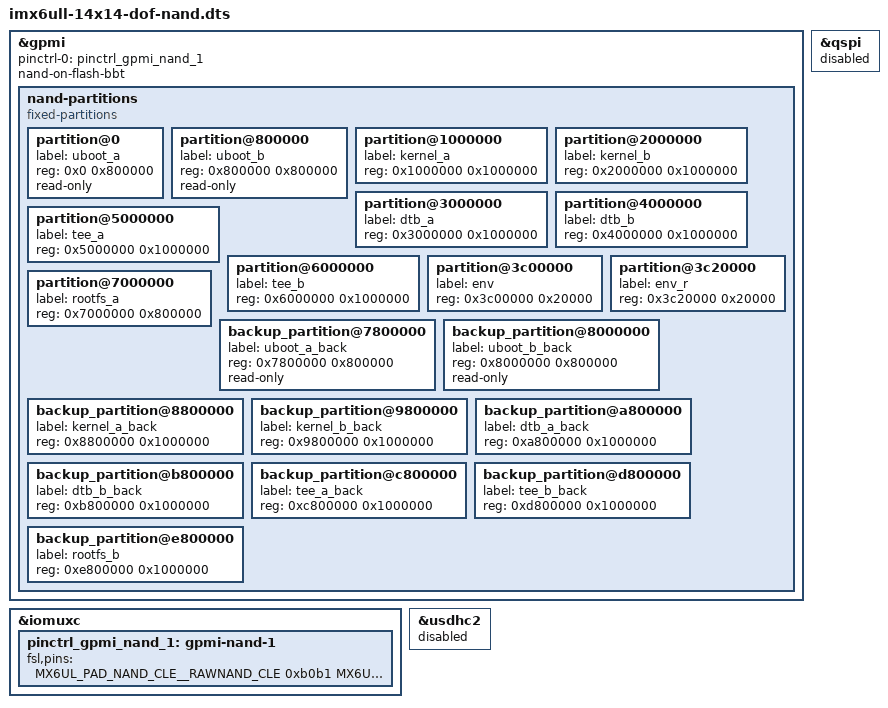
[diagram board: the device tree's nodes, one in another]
// SPDX-License-Identifier: GPL-2.0
//
// Copyright (C) 2016 Freescale Semiconductor, Inc.

#include "imx6ull-14x14-dof.dts"

&gpmi {
	pinctrl-names = "default";
	pinctrl-0 = <&pinctrl_gpmi_nand_1>;
	status = "okay";
	nand-on-flash-bbt;

	nand-partitions {
		compatible = "fixed-partitions";
		#address-cells = <1>;
		#size-cells = <1>;

		partition@0 {
			label = "uboot_a";
			reg = <0x0 0x800000>;
			read-only;
		};

		partition@800000 {
			label = "uboot_b";
			reg = <0x800000 0x800000>;
			read-only;
		};

		partition@1000000 {
			label = "kernel_a";
			reg = <0x1000000 0x1000000>;
		};

		partition@2000000 {
			label = "kernel_b";
			reg = <0x2000000 0x1000000>;
		};

		partition@3000000 {
			label = "dtb_a";
			reg = <0x3000000 0x1000000>;
		};

		partition@4000000 {
			label = "dtb_b";
			reg = <0x4000000 0x1000000>;
		};

		partition@5000000 {
			label = "tee_a";
			reg = <0x5000000 0x1000000>;
		};

		partition@6000000 {
			label = "tee_b";
			reg = <0x6000000 0x1000000>;
		};

		partition@3c00000 {
			label = "env";
			reg = <0x3c00000 0x20000>;
		};

		partition@3c20000 {
			label = "env_r";
			reg = <0x3c20000 0x20000>;
		};

		partition@7000000 {
			label = "rootfs_a";
			reg = <0x7000000 0x800000>; /* This will be dynamic in real use */
		};

		/* Backup partitions */
		backup_partition@7800000 {
			label = "uboot_a_back";
			reg = <0x7800000 0x800000>;
			read-only;
		};

		backup_partition@8000000 {
			label = "uboot_b_back";
			reg = <0x8000000 0x800000>;
			read-only;
		};

		backup_partition@8800000 {
			label = "kernel_a_back";
			reg = <0x8800000 0x1000000>;
		};

		backup_partition@9800000 {
			label = "kernel_b_back";
			reg = <0x9800000 0x1000000>;
		};

		backup_partition@a800000 {
			label = "dtb_a_back";
			reg = <0xa800000 0x1000000>;
		};

		backup_partition@b800000 {
			label = "dtb_b_back";
			reg = <0xb800000 0x1000000>;
		};

		backup_partition@c800000 {
			label = "tee_a_back";
			reg = <0xc800000 0x1000000>;
		};

		backup_partition@d800000 {
			label = "tee_b_back";
			reg = <0xd800000 0x1000000>;
		};

		backup_partition@e800000 {
			label = "rootfs_b";
			reg = <0xe800000 0x1000000>;
		};
	};
};

&iomuxc {
	pinctrl_gpmi_nand_1: gpmi-nand-1 {
		fsl,pins = <
			MX6UL_PAD_NAND_CLE__RAWNAND_CLE         0xb0b1
			MX6UL_PAD_NAND_ALE__RAWNAND_ALE         0xb0b1
			MX6UL_PAD_NAND_WP_B__RAWNAND_WP_B       0xb0b1
			MX6UL_PAD_NAND_READY_B__RAWNAND_READY_B 0xb000
			MX6UL_PAD_NAND_CE0_B__RAWNAND_CE0_B     0xb0b1
			MX6UL_PAD_NAND_CE1_B__RAWNAND_CE1_B     0xb0b1
			MX6UL_PAD_NAND_RE_B__RAWNAND_RE_B       0xb0b1
			MX6UL_PAD_NAND_WE_B__RAWNAND_WE_B       0xb0b1
			MX6UL_PAD_NAND_DATA00__RAWNAND_DATA00   0xb0b1
			MX6UL_PAD_NAND_DATA01__RAWNAND_DATA01   0xb0b1
			MX6UL_PAD_NAND_DATA02__RAWNAND_DATA02   0xb0b1
			MX6UL_PAD_NAND_DATA03__RAWNAND_DATA03   0xb0b1
			MX6UL_PAD_NAND_DATA04__RAWNAND_DATA04   0xb0b1
			MX6UL_PAD_NAND_DATA05__RAWNAND_DATA05   0xb0b1
			MX6UL_PAD_NAND_DATA06__RAWNAND_DATA06   0xb0b1
			MX6UL_PAD_NAND_DATA07__RAWNAND_DATA07   0xb0b1
		>;
	};
};

&qspi {
	status = "disabled";
};

&usdhc2 {
	status = "disabled";
};
